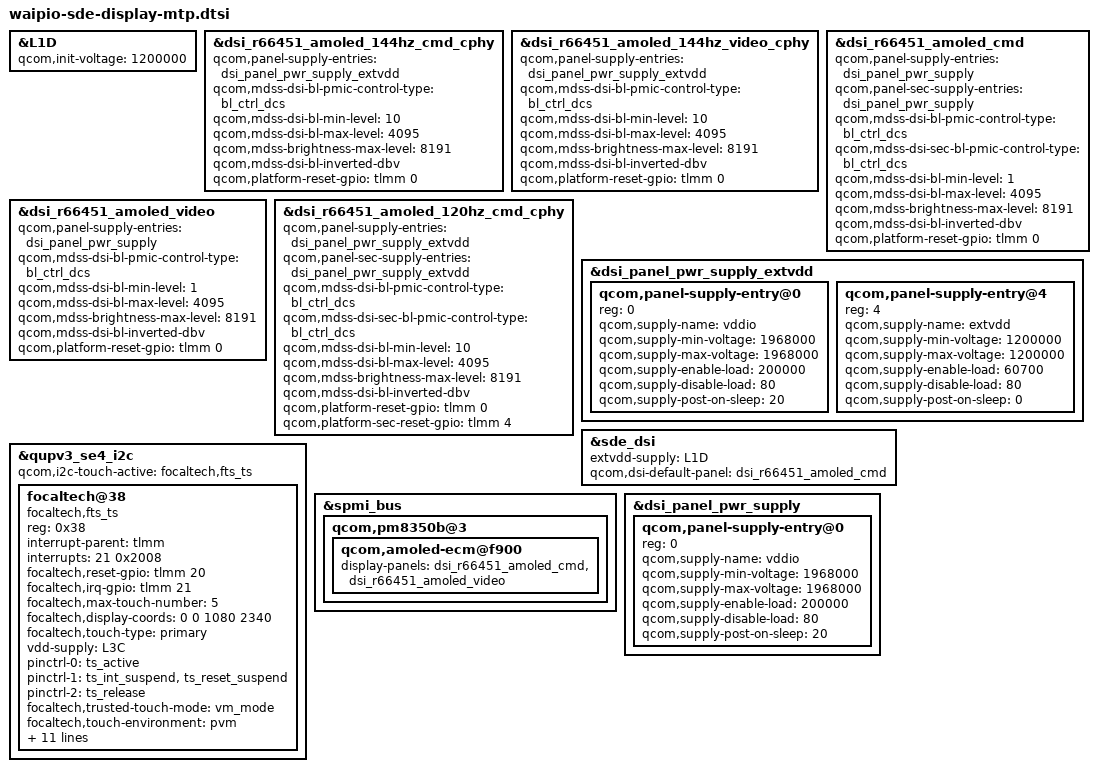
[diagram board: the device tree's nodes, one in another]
// SPDX-License-Identifier: BSD-3-Clause
/*
 * Copyright (c) Qualcomm Technologies, Inc. and/or its subsidiaries.
 */

#include "waipio-sde-display.dtsi"

&L1D {
	qcom,init-voltage = <1200000>; /* panel ext vdd */
};

&dsi_r66451_amoled_144hz_cmd_cphy {
	qcom,panel-supply-entries = <&dsi_panel_pwr_supply_extvdd>;
	qcom,mdss-dsi-bl-pmic-control-type = "bl_ctrl_dcs";
	qcom,mdss-dsi-bl-min-level = <10>;
	qcom,mdss-dsi-bl-max-level = <4095>;
	qcom,mdss-brightness-max-level = <8191>;
	qcom,mdss-dsi-bl-inverted-dbv;
	qcom,platform-reset-gpio = <&tlmm 0 0>;
};

&dsi_r66451_amoled_144hz_video_cphy {
	qcom,panel-supply-entries = <&dsi_panel_pwr_supply_extvdd>;
	qcom,mdss-dsi-bl-pmic-control-type = "bl_ctrl_dcs";
	qcom,mdss-dsi-bl-min-level = <10>;
	qcom,mdss-dsi-bl-max-level = <4095>;
	qcom,mdss-brightness-max-level = <8191>;
	qcom,mdss-dsi-bl-inverted-dbv;
	qcom,platform-reset-gpio = <&tlmm 0 0>;
};

&dsi_r66451_amoled_cmd {
	qcom,panel-supply-entries = <&dsi_panel_pwr_supply>;
	qcom,panel-sec-supply-entries = <&dsi_panel_pwr_supply>;
	qcom,mdss-dsi-bl-pmic-control-type = "bl_ctrl_dcs";
	qcom,mdss-dsi-sec-bl-pmic-control-type = "bl_ctrl_dcs";
	qcom,mdss-dsi-bl-min-level = <1>;
	qcom,mdss-dsi-bl-max-level = <4095>;
	qcom,mdss-brightness-max-level = <8191>;
	qcom,mdss-dsi-bl-inverted-dbv;
	qcom,platform-reset-gpio = <&tlmm 0 0>;
};

&dsi_r66451_amoled_video {
	qcom,panel-supply-entries = <&dsi_panel_pwr_supply>;
	qcom,mdss-dsi-bl-pmic-control-type = "bl_ctrl_dcs";
	qcom,mdss-dsi-bl-min-level = <1>;
	qcom,mdss-dsi-bl-max-level = <4095>;
	qcom,mdss-brightness-max-level = <8191>;
	qcom,mdss-dsi-bl-inverted-dbv;
	qcom,platform-reset-gpio = <&tlmm 0 0>;
};

&dsi_r66451_amoled_120hz_cmd_cphy {
        qcom,panel-supply-entries = <&dsi_panel_pwr_supply_extvdd>;
        qcom,panel-sec-supply-entries = <&dsi_panel_pwr_supply_extvdd>;
        qcom,mdss-dsi-bl-pmic-control-type = "bl_ctrl_dcs";
        qcom,mdss-dsi-sec-bl-pmic-control-type = "bl_ctrl_dcs";
        qcom,mdss-dsi-bl-min-level = <10>;
        qcom,mdss-dsi-bl-max-level = <4095>;
        qcom,mdss-brightness-max-level = <8191>;
        qcom,mdss-dsi-bl-inverted-dbv;
        qcom,platform-reset-gpio = <&tlmm 0 0>;
        qcom,platform-sec-reset-gpio = <&tlmm 4 0>;
};


&dsi_panel_pwr_supply_extvdd {
	qcom,panel-supply-entry@0 {
		reg = <0>;
		qcom,supply-name = "vddio";
		qcom,supply-min-voltage = <1968000>;
		qcom,supply-max-voltage = <1968000>;
		qcom,supply-enable-load = <200000>;
		qcom,supply-disable-load = <80>;
		qcom,supply-post-on-sleep = <20>;
	};

	qcom,panel-supply-entry@4 {
		reg = <4>;
		qcom,supply-name = "extvdd";
		qcom,supply-min-voltage = <1200000>;
		qcom,supply-max-voltage = <1200000>;
		qcom,supply-enable-load = <60700>;
		qcom,supply-disable-load = <80>;
		qcom,supply-post-on-sleep = <0>;
	};
};

&sde_dsi {
	extvdd-supply = <&L1D>;
	qcom,dsi-default-panel = <&dsi_r66451_amoled_cmd>;
};

&qupv3_se4_i2c {
	qcom,i2c-touch-active = "focaltech,fts_ts";
	focaltech@38 {
		compatible = "focaltech,fts_ts";
                reg = <0x38>;
                interrupt-parent = <&tlmm>;
                interrupts = <21 0x2008>;
                focaltech,reset-gpio = <&tlmm 20 0x00>;
                focaltech,irq-gpio = <&tlmm 21 0x2008>;
                focaltech,max-touch-number = <5>;
                focaltech,display-coords = <0 0 1080 2340>;
                focaltech,touch-type = "primary";

                vdd-supply = <&L3C>;

                pinctrl-names = "pmx_ts_active", "pmx_ts_suspend","pmx_ts_release";
                pinctrl-0 = <&ts_active>;
                pinctrl-1 = <&ts_int_suspend &ts_reset_suspend>;
                pinctrl-2 = <&ts_release>;
                focaltech,trusted-touch-mode = "vm_mode";
                focaltech,touch-environment = "pvm";
                focaltech,trusted-touch-type = "primary";
                focaltech,trusted-touch-spi-irq = <754>;
                focaltech,trusted-touch-io-bases = <0x990000 0x910000>;
                focaltech,trusted-touch-io-sizes = <0x1000 0x4000>;
                focaltech,trusted-touch-vm-gpio-list = <&tlmm 16 0 &tlmm 17 0 &tlmm 18 0
                                                &tlmm 19 0 &tlmm 20 0 &tlmm 21 0x2008>;
		panel = <&dsi_r66451_amoled_cmd
			&dsi_r66451_amoled_video>;
	};
};

&spmi_bus {
	qcom,pm8350b@3 {
		qcom,amoled-ecm@f900 {
			display-panels = <&dsi_r66451_amoled_cmd
					&dsi_r66451_amoled_video>;
		};
	};
};

&dsi_panel_pwr_supply {
		qcom,panel-supply-entry@0 {
			reg = <0>;
			qcom,supply-name = "vddio";
			qcom,supply-min-voltage = <1968000>;
			qcom,supply-max-voltage = <1968000>;
			qcom,supply-enable-load = <200000>;
			qcom,supply-disable-load = <80>;
			qcom,supply-post-on-sleep = <20>;
		};
};
